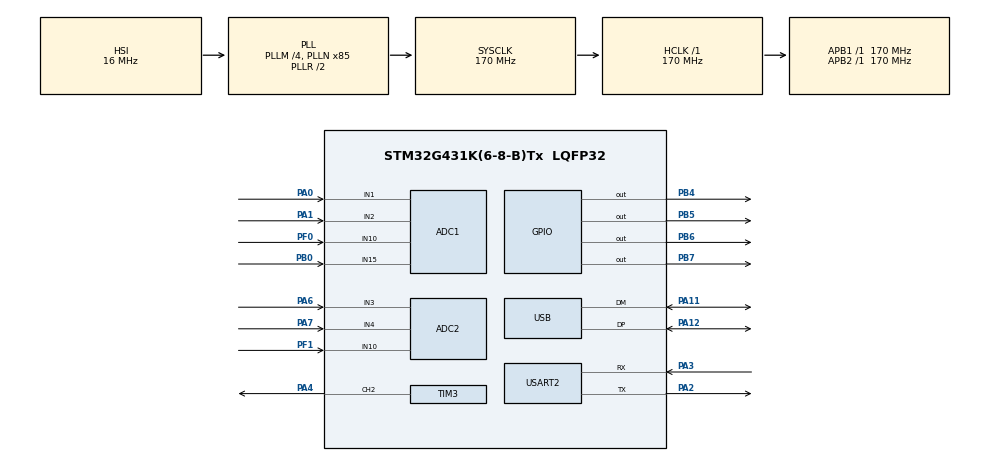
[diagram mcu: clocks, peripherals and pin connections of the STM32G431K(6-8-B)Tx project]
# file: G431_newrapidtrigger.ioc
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ADC1.Channel-0\#ChannelRegularConversion=ADC_CHANNEL_1
ADC1.NbrOfConversionFlag=1
ADC1.OffsetNumber-0\#ChannelRegularConversion=ADC_OFFSET_NONE
ADC1.Rank-0\#ChannelRegularConversion=1
ADC1.SamplingTime-0\#ChannelRegularConversion=ADC_SAMPLETIME_24CYCLES_5
ADC1.master=1
ADC2.Channel-0\#ChannelRegularConversion=ADC_CHANNEL_3
ADC2.NbrOfConversionFlag=1
ADC2.OffsetNumber-0\#ChannelRegularConversion=ADC_OFFSET_NONE
ADC2.Rank-0\#ChannelRegularConversion=1
ADC2.SamplingTime-0\#ChannelRegularConversion=ADC_SAMPLETIME_24CYCLES_5
Mcu.Family=STM32G4
Mcu.Name=STM32G431K(6-8-B)Tx
Mcu.Package=LQFP32
NVIC.PriorityGroup=NVIC_PRIORITYGROUP_4
NVIC.TIM6_DAC_IRQn=true\:2\:0\:true\:false\:true\:true\:true\:true
NVIC.USB_LP_IRQn=true\:0\:0\:false\:false\:true\:false\:true\:true
PA0.Mode=IN1-Single-Ended
PA0.Signal=ADC1_IN1
PA1.Mode=IN2-Single-Ended
PA1.Signal=ADC1_IN2
PA11.Mode=Device
PA11.Signal=USB_DM
PA12.Mode=Device
PA12.Signal=USB_DP
PA13.Mode=Serial_Wire
PA13.Signal=SYS_JTMS-SWDIO
PA14.Mode=Serial_Wire
PA14.Signal=SYS_JTCK-SWCLK
PA2.Mode=Asynchronous
PA2.Signal=USART2_TX
PA3.Mode=Asynchronous
PA3.Signal=USART2_RX
PA4.Signal=S_TIM3_CH2
PA6.Mode=IN3-Single-Ended
PA6.Signal=ADC2_IN3
PA7.Mode=IN4-Single-Ended
PA7.Signal=ADC2_IN4
PB0.Mode=IN15-Single-Ended
PB0.Signal=ADC1_IN15
PB4.Signal=GPIO_Output
PB5.Signal=GPIO_Output
PB6.Signal=GPIO_Output
PB7.Signal=GPIO_Output
PF0-OSC_IN.Mode=IN10-Single-Ended
PF0-OSC_IN.Signal=ADC1_IN10
PF1-OSC_OUT.Mode=IN10-Single-Ended
PF1-OSC_OUT.Signal=ADC2_IN10
ProjectManager.HeapSize=0x1000
ProjectManager.StackSize=0x1000
ProjectManager.TargetToolchain=CMake
RCC.ADC12Freq_Value=170000000
RCC.AHBFreq_Value=170000000
RCC.APB1Freq_Value=170000000
RCC.APB1TimFreq_Value=170000000
RCC.APB2Freq_Value=170000000
RCC.APB2TimFreq_Value=170000000
RCC.CK48CLockSelection=RCC_USBCLKSOURCE_HSI48
RCC.CortexFreq_Value=170000000
RCC.EXTERNAL_CLOCK_VALUE=12288000
RCC.HCLKFreq_Value=170000000
RCC.HSE_VALUE=8000000
RCC.HSI48_VALUE=48000000
RCC.HSI_VALUE=16000000
RCC.LSE_VALUE=32768
RCC.PLLM=RCC_PLLM_DIV4
RCC.PLLN=85
RCC.PLLQ=RCC_PLLQ_DIV4
RCC.SYSCLKFreq_VALUE=170000000
RCC.SYSCLKSource=RCC_SYSCLKSOURCE_PLLCLK
RCC.USBFreq_Value=48000000
RCC.VCOOutputFreq_Value=340000000
SH.S_TIM3_CH2.0=TIM3_CH2,PWM Generation2 CH2
TIM3.Channel-PWM\ Generation2\ CH2=TIM_CHANNEL_2
USART2.VirtualMode-Asynchronous=VM_ASYNC
USB_DEVICE.CLASS_NAME_FS=CUSTOM_HID
USB_DEVICE.CUSTOM_HID_FS_BINTERVAL=0x1
USB_DEVICE.USBD_CUSTOMHID_OUTREPORT_BUF_SIZE=33
USB_DEVICE.USBD_CUSTOM_HID_REPORT_DESC_SIZE=61
USB_DEVICE.VirtualMode=CustomHid
USB_DEVICE.VirtualModeFS=Custom_Hid_FS
VP_RCC_VS_USB.Mode=USB_FS
VP_SYS_VS_DBSignals.Mode=DisableDeadBatterySignals
VP_TIM6_VS_ClockSourceINT.Mode=Enable_Timer
VP_USB_DEVICE_VS_USB_DEVICE_CUSTOM_HID_FS.Mode=CUSTOM_HID_FS
board=custom

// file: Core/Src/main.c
/* USER CODE BEGIN Header */
/**
  ******************************************************************************
  * @file           : main.c
  * @brief          : Main program body
  ******************************************************************************
  * @attention
  *
  * Copyright (c) 2026 STMicroelectronics.
  * All rights reserved.
  *
  * This software is licensed under terms that can be found in the LICENSE file
  * in the root directory of this software component.
  * If no LICENSE file comes with this software, it is provided AS-IS.
  *
  ******************************************************************************
  */
/* USER CODE END Header */
#include "main.h"
#include "adc.h"
#include "tim.h"
#include "usart.h"
#include "usb_device.h"
#include "gpio.h"

/* USER CODE BEGIN Includes */
#include "main.hpp"
#include<stdio.h>

/* USER CODE END Includes */

void SystemClock_Config(void);
/* USER CODE BEGIN PFP */
void setup(void);
void loop(void);

/* USER CODE END PFP */

int main(void)
{

  /* USER CODE BEGIN 1 */
  setbuf(stdout, NULL);

  /* USER CODE END 1 */

  /* MCU Configuration--------------------------------------------------------*/

  /* Reset of all peripherals, Initializes the Flash interface and the Systick. */
  HAL_Init();

  /* Configure the system clock */
  SystemClock_Config();

  /* Initialize all configured peripherals */
  MX_GPIO_Init();
  MX_ADC1_Init();
  MX_ADC2_Init();
  MX_USART2_UART_Init();
  MX_USB_Device_Init();
  MX_TIM3_Init();
  MX_TIM6_Init();
  /* USER CODE BEGIN 2 */
  setup();

  /* USER CODE END 2 */

  /* Infinite loop */
  while (1)
  {

    /* USER CODE BEGIN 3 */
    loop();
  }
  /* USER CODE END 3 */
}

void SystemClock_Config(void)
{
  RCC_OscInitTypeDef RCC_OscInitStruct = {0};
  RCC_ClkInitTypeDef RCC_ClkInitStruct = {0};
  RCC_CRSInitTypeDef pInit = {0};

  /** Configure the main internal regulator output voltage
  */
  HAL_PWREx_ControlVoltageScaling(PWR_REGULATOR_VOLTAGE_SCALE1_BOOST);

  /** Initializes the RCC Oscillators according to the specified parameters
  * in the RCC_OscInitTypeDef structure.
  */
  RCC_OscInitStruct.OscillatorType = RCC_OSCILLATORTYPE_HSI|RCC_OSCILLATORTYPE_HSI48;
  RCC_OscInitStruct.HSIState = RCC_HSI_ON;
  RCC_OscInitStruct.HSICalibrationValue = RCC_HSICALIBRATION_DEFAULT;
  RCC_OscInitStruct.HSI48State = RCC_HSI48_ON;
  RCC_OscInitStruct.PLL.PLLState = RCC_PLL_ON;
  RCC_OscInitStruct.PLL.PLLSource = RCC_PLLSOURCE_HSI;
  RCC_OscInitStruct.PLL.PLLM = RCC_PLLM_DIV4;
  RCC_OscInitStruct.PLL.PLLN = 85;
  RCC_OscInitStruct.PLL.PLLP = RCC_PLLP_DIV2;
  RCC_OscInitStruct.PLL.PLLQ = RCC_PLLQ_DIV4;
  RCC_OscInitStruct.PLL.PLLR = RCC_PLLR_DIV2;
  if (HAL_RCC_OscConfig(&RCC_OscInitStruct) != HAL_OK)
  {
    Error_Handler();
  }

  /** Initializes the CPU, AHB and APB buses clocks
  */
  RCC_ClkInitStruct.ClockType = RCC_CLOCKTYPE_HCLK|RCC_CLOCKTYPE_SYSCLK
                              |RCC_CLOCKTYPE_PCLK1|RCC_CLOCKTYPE_PCLK2;
  RCC_ClkInitStruct.SYSCLKSource = RCC_SYSCLKSOURCE_PLLCLK;
  RCC_ClkInitStruct.AHBCLKDivider = RCC_SYSCLK_DIV1;
  RCC_ClkInitStruct.APB1CLKDivider = RCC_HCLK_DIV1;
  RCC_ClkInitStruct.APB2CLKDivider = RCC_HCLK_DIV1;

  if (HAL_RCC_ClockConfig(&RCC_ClkInitStruct, FLASH_LATENCY_4) != HAL_OK)
  {
    Error_Handler();
  }

  /** Enable the SYSCFG APB clock
  */
  __HAL_RCC_CRS_CLK_ENABLE();

  /** Configures CRS
  */
  pInit.Prescaler = RCC_CRS_SYNC_DIV1;
  pInit.Source = RCC_CRS_SYNC_SOURCE_USB;
  pInit.Polarity = RCC_CRS_SYNC_POLARITY_RISING;
  pInit.ReloadValue = __HAL_RCC_CRS_RELOADVALUE_CALCULATE(48000000,1000);
  pInit.ErrorLimitValue = 34;
  pInit.HSI48CalibrationValue = 32;

  HAL_RCCEx_CRSConfig(&pInit);
}

/* USER CODE BEGIN 4 */
int __io_putchar(int ch)
{
  HAL_UART_Transmit(&huart2, (uint8_t *)&ch, 1, 0xFFFF);
  return ch;
}

/* USER CODE END 4 */

void Error_Handler(void)
{
  __disable_irq();
  while (1)
  {
  }
}
